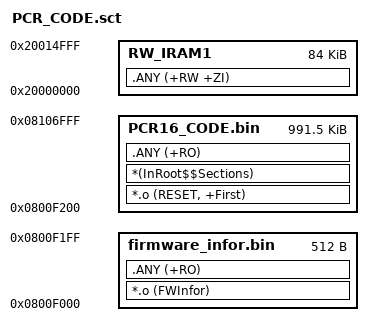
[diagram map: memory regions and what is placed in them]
; *************************************************************
; *** Scatter-Loading Description File generated by uVision ***
; *************************************************************
LR_IROM1 0x0800F000 0x00200  {
  firmware_infor.bin 0x0800F000 0x00200	{
	*.o (FWInfor)
	.ANY (+RO)	
  }
}

LR_IROM2 0x0800F200 0x00f0e00  {    ; load region size_region
  PCR16_CODE.bin 0x0800F200 0x00f7e00  {  ; load address = execution address
	*.o (RESET, +First)
	*(InRoot$$Sections)
	.ANY (+RO)	
  }
  RW_IRAM1 0x20000000 0x00015000  {  ; RW data
   .ANY (+RW +ZI)
  }
}

